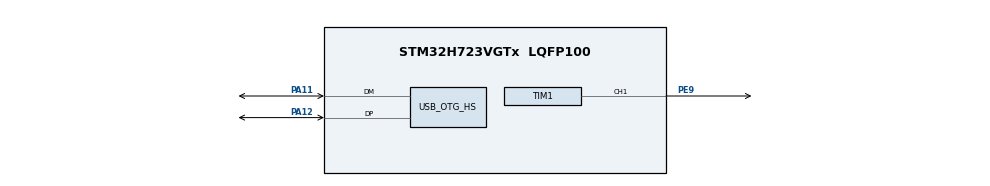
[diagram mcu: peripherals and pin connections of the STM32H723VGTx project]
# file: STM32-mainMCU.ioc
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CORTEX_M7.default_mode_Activation=1
Dma.Request0=TIM1_CH1
Dma.TIM1_CH1.0.Direction=DMA_MEMORY_TO_PERIPH
Dma.TIM1_CH1.0.EventEnable=DISABLE
Dma.TIM1_CH1.0.FIFOMode=DMA_FIFOMODE_DISABLE
Dma.TIM1_CH1.0.Instance=DMA1_Stream0
Dma.TIM1_CH1.0.MemDataAlignment=DMA_MDATAALIGN_HALFWORD
Dma.TIM1_CH1.0.MemInc=DMA_MINC_ENABLE
Dma.TIM1_CH1.0.Mode=DMA_NORMAL
Dma.TIM1_CH1.0.PeriphDataAlignment=DMA_PDATAALIGN_HALFWORD
Dma.TIM1_CH1.0.PeriphInc=DMA_PINC_DISABLE
Dma.TIM1_CH1.0.Polarity=HAL_DMAMUX_REQ_GEN_RISING
Dma.TIM1_CH1.0.Priority=DMA_PRIORITY_LOW
Dma.TIM1_CH1.0.RequestNumber=1
Dma.TIM1_CH1.0.SignalID=NONE
Dma.TIM1_CH1.0.SyncEnable=DISABLE
Dma.TIM1_CH1.0.SyncPolarity=HAL_DMAMUX_SYNC_NO_EVENT
Dma.TIM1_CH1.0.SyncRequestNumber=1
Dma.TIM1_CH1.0.SyncSignalID=NONE
Mcu.Family=STM32H7
Mcu.Name=STM32H723VGTx
Mcu.Package=LQFP100
NVIC.DMA1_Stream0_IRQn=true\:0\:0\:false\:false\:true\:false\:true\:true
NVIC.OTG_HS_IRQn=true\:0\:0\:false\:false\:true\:false\:true\:true
NVIC.PriorityGroup=NVIC_PRIORITYGROUP_4
PA11.Mode=Device_Only_FS
PA11.Signal=USB_OTG_HS_DM
PA12.Mode=Device_Only_FS
PA12.Signal=USB_OTG_HS_DP
PA13(JTMS/SWDIO).Mode=Trace_Asynchronous_SW
PA13(JTMS/SWDIO).Signal=DEBUG_JTMS-SWDIO
PA14(JTCK/SWCLK).Mode=Trace_Asynchronous_SW
PA14(JTCK/SWCLK).Signal=DEBUG_JTCK-SWCLK
PB3(JTDO/TRACESWO).Mode=Trace_Asynchronous_SW
PB3(JTDO/TRACESWO).Signal=DEBUG_JTDO-SWO
PC14-OSC32_IN.Mode=LSE-External-Oscillator
PC14-OSC32_IN.Signal=RCC_OSC32_IN
PC15-OSC32_OUT.Mode=LSE-External-Oscillator
PC15-OSC32_OUT.Signal=RCC_OSC32_OUT
PE9.Signal=S_TIM1_CH1
PH0-OSC_IN.Mode=HSE-External-Oscillator
PH0-OSC_IN.Signal=RCC_OSC_IN
PH1-OSC_OUT.Mode=HSE-External-Oscillator
PH1-OSC_OUT.Signal=RCC_OSC_OUT
ProjectManager.HeapSize=0x200
ProjectManager.StackSize=0x400
ProjectManager.TargetToolchain=STM32CubeIDE
RCC.ADCFreq_Value=50390625
RCC.APB1Freq_Value=64000000
RCC.APB2Freq_Value=64000000
RCC.APB3Freq_Value=64000000
RCC.APB4Freq_Value=64000000
RCC.CortexFreq_Value=64000000
RCC.DIVM1=5
RCC.DIVN1=48
RCC.DIVQ1=5
RCC.HCLKFreq_Value=64000000
RCC.PLLFRACN=0
RCC.SYSCLKFreq_VALUE=64000000
RCC.USBFreq_Value=48000000
SH.S_TIM1_CH1.0=TIM1_CH1,PWM Generation1 CH1
TIM1.Channel-PWM\ Generation1\ CH1=TIM_CHANNEL_1
TIM1.Period=80
USB_DEVICE.CLASS_NAME_HS=CDC
USB_DEVICE.PRODUCT_STRING_CDC_HS=ULP3.0-Portable
USB_DEVICE.VirtualMode=Cdc
USB_DEVICE.VirtualModeHS=Cdc_HS
USB_OTG_HS.VirtualMode-Device_Only_FS=Device_Only_FS
VP_TIM1_VS_ClockSourceINT.Mode=Internal
VP_USB_DEVICE_VS_USB_DEVICE_CDC_HS.Mode=CDC_HS
board=custom

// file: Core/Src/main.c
/* USER CODE BEGIN Header */
/**
  ******************************************************************************
  * @file           : main.c
  * @brief          : Main program body
  ******************************************************************************
  * @attention
  *
  * Copyright (c) 2024 STMicroelectronics.
  * All rights reserved.
  *
  * This software is licensed under terms that can be found in the LICENSE file
  * in the root directory of this software component.
  * If no LICENSE file comes with this software, it is provided AS-IS.
  *
  ******************************************************************************
  */
/* USER CODE END Header */
#include "main.h"
#include "dma.h"
#include "tim.h"
#include "usb_device.h"
#include "gpio.h"

/* USER CODE BEGIN Includes */
#include "ULP_ws2812b.h"
#include "ULP_strip_effects.h"
#include "ULP_utilities.h"
/* USER CODE END Includes */

void SystemClock_Config(void);
static void MPU_Config(void);

/* USER CODE BEGIN 0 */

volatile uint8_t dma_flag = 0;

void HAL_TIM_PWM_PulseFinishedCallback(TIM_HandleTypeDef *htim)
{
	HAL_TIM_PWM_Stop(htim, TIM_CHANNEL_1);
	dma_flag = 0;
}

/* USER CODE END 0 */

int main(void)
{

  /* MPU Configuration--------------------------------------------------------*/
  MPU_Config();

  /* MCU Configuration--------------------------------------------------------*/

  /* Reset of all peripherals, Initializes the Flash interface and the Systick. */
  HAL_Init();

  /* Configure the system clock */
  SystemClock_Config();

  /* Initialize all configured peripherals */
  MX_GPIO_Init();
  MX_DMA_Init();
  MX_USB_DEVICE_Init();
  MX_TIM1_Init();
  /* USER CODE BEGIN 2 */

  uint8_t color_array[21][3];
  uint16_t pixel_bit_buffer[(21 * 24) + 45];

  strip_startup_init();
  clear_led_strip(color_array, 21);

  while(1)
  {
	  color_array_to_pixels(color_array, pixel_bit_buffer, 21, 100);
	  if (!run_strip_startup_effect(color_array, 21))
		  break;

	  while(dma_flag);
	  HAL_TIM_PWM_Start_DMA(&htim1, TIM_CHANNEL_1, (uint32_t*)pixel_bit_buffer, buffer_size(21));
	  dma_flag = 1;

	  HAL_Delay(25);
  }

  get_gradient(0, 0, 255, 255, 0, 0, color_array, 21);

  color_array_to_pixels(color_array, pixel_bit_buffer, 21, 100);
  HAL_TIM_PWM_Start_DMA(&htim1, TIM_CHANNEL_1, (uint32_t*)pixel_bit_buffer, buffer_size(21));
  while(dma_flag);

  /* USER CODE END 2 */

  /* Infinite loop */
  /* USER CODE BEGIN WHILE */
  while (1)
  {
	  move_pixel_right(color_array, 21);
	  color_array_to_pixels(color_array, pixel_bit_buffer, 21, 100);
	  HAL_TIM_PWM_Start_DMA(&htim1, TIM_CHANNEL_1, (uint32_t*)pixel_bit_buffer, buffer_size(21));
	  while(dma_flag);
	  HAL_Delay(20);

    /* USER CODE END WHILE */

  }
}

void SystemClock_Config(void)
{
  RCC_OscInitTypeDef RCC_OscInitStruct = {0};
  RCC_ClkInitTypeDef RCC_ClkInitStruct = {0};

  /** Supply configuration update enable
  */
  HAL_PWREx_ConfigSupply(PWR_LDO_SUPPLY);

  /** Configure the main internal regulator output voltage
  */
  __HAL_PWR_VOLTAGESCALING_CONFIG(PWR_REGULATOR_VOLTAGE_SCALE3);

  while(!__HAL_PWR_GET_FLAG(PWR_FLAG_VOSRDY)) {}

  /** Initializes the RCC Oscillators according to the specified parameters
  * in the RCC_OscInitTypeDef structure.
  */
  RCC_OscInitStruct.OscillatorType = RCC_OSCILLATORTYPE_HSI|RCC_OSCILLATORTYPE_HSE;
  RCC_OscInitStruct.HSEState = RCC_HSE_ON;
  RCC_OscInitStruct.HSIState = RCC_HSI_DIV1;
  RCC_OscInitStruct.HSICalibrationValue = 64;
  RCC_OscInitStruct.PLL.PLLState = RCC_PLL_ON;
  RCC_OscInitStruct.PLL.PLLSource = RCC_PLLSOURCE_HSE;
  RCC_OscInitStruct.PLL.PLLM = 5;
  RCC_OscInitStruct.PLL.PLLN = 48;
  RCC_OscInitStruct.PLL.PLLP = 2;
  RCC_OscInitStruct.PLL.PLLQ = 5;
  RCC_OscInitStruct.PLL.PLLR = 2;
  RCC_OscInitStruct.PLL.PLLRGE = RCC_PLL1VCIRANGE_2;
  RCC_OscInitStruct.PLL.PLLVCOSEL = RCC_PLL1VCOWIDE;
  RCC_OscInitStruct.PLL.PLLFRACN = 0;
  if (HAL_RCC_OscConfig(&RCC_OscInitStruct) != HAL_OK)
  {
    Error_Handler();
  }

  /** Initializes the CPU, AHB and APB buses clocks
  */
  RCC_ClkInitStruct.ClockType = RCC_CLOCKTYPE_HCLK|RCC_CLOCKTYPE_SYSCLK
                              |RCC_CLOCKTYPE_PCLK1|RCC_CLOCKTYPE_PCLK2
                              |RCC_CLOCKTYPE_D3PCLK1|RCC_CLOCKTYPE_D1PCLK1;
  RCC_ClkInitStruct.SYSCLKSource = RCC_SYSCLKSOURCE_HSI;
  RCC_ClkInitStruct.SYSCLKDivider = RCC_SYSCLK_DIV1;
  RCC_ClkInitStruct.AHBCLKDivider = RCC_HCLK_DIV1;
  RCC_ClkInitStruct.APB3CLKDivider = RCC_APB3_DIV1;
  RCC_ClkInitStruct.APB1CLKDivider = RCC_APB1_DIV1;
  RCC_ClkInitStruct.APB2CLKDivider = RCC_APB2_DIV1;
  RCC_ClkInitStruct.APB4CLKDivider = RCC_APB4_DIV1;

  if (HAL_RCC_ClockConfig(&RCC_ClkInitStruct, FLASH_LATENCY_1) != HAL_OK)
  {
    Error_Handler();
  }
}

 /* MPU Configuration */

void MPU_Config(void)
{
  MPU_Region_InitTypeDef MPU_InitStruct = {0};

  /* Disables the MPU */
  HAL_MPU_Disable();

  /** Initializes and configures the Region and the memory to be protected
  */
  MPU_InitStruct.Enable = MPU_REGION_ENABLE;
  MPU_InitStruct.Number = MPU_REGION_NUMBER0;
  MPU_InitStruct.BaseAddress = 0x0;
  MPU_InitStruct.Size = MPU_REGION_SIZE_4GB;
  MPU_InitStruct.SubRegionDisable = 0x87;
  MPU_InitStruct.TypeExtField = MPU_TEX_LEVEL0;
  MPU_InitStruct.AccessPermission = MPU_REGION_NO_ACCESS;
  MPU_InitStruct.DisableExec = MPU_INSTRUCTION_ACCESS_DISABLE;
  MPU_InitStruct.IsShareable = MPU_ACCESS_SHAREABLE;
  MPU_InitStruct.IsCacheable = MPU_ACCESS_NOT_CACHEABLE;
  MPU_InitStruct.IsBufferable = MPU_ACCESS_NOT_BUFFERABLE;

  HAL_MPU_ConfigRegion(&MPU_InitStruct);
  /* Enables the MPU */
  HAL_MPU_Enable(MPU_PRIVILEGED_DEFAULT);

}

void Error_Handler(void)
{
  __disable_irq();
  while (1)
  {
  }
}
